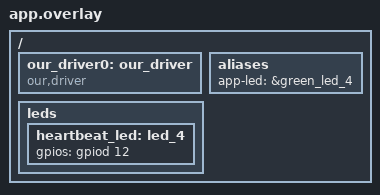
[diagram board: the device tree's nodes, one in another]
/{

    our_driver0:our_driver{
        compatible = "our,driver";
        status  = "okay";
    };
    aliases{
        app-led = &green_led_4;
    };

    leds{
        heartbeat_led:led_4{
           gpios = <&gpiod 12  GPIO_ACTIVE_HIGH> ;
        };

    };
};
